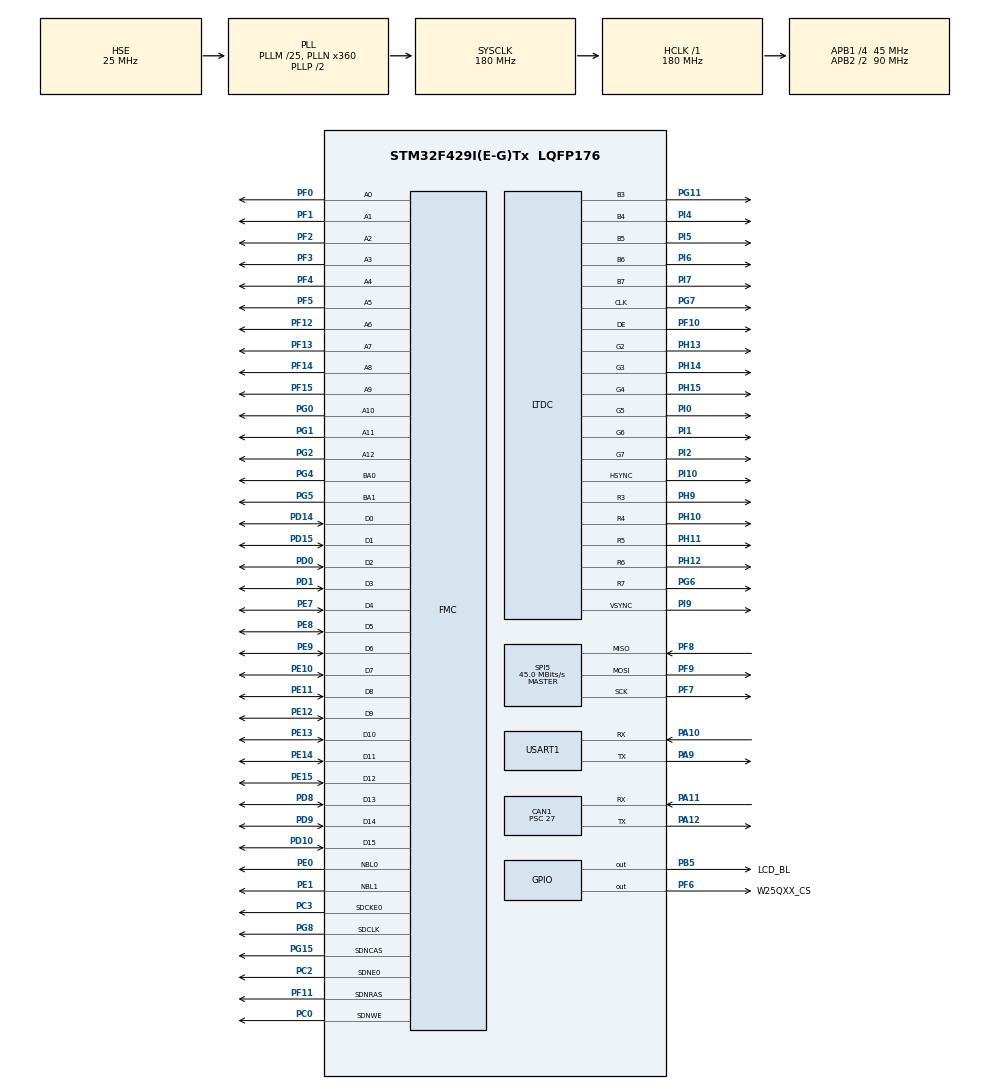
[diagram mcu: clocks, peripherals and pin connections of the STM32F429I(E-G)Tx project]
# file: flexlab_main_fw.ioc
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CAN1.ABOM=DISABLE
CAN1.AWUM=DISABLE
CAN1.BS1=CAN_BS1_5TQ
CAN1.BS2=CAN_BS2_5TQ
CAN1.CalculateBaudRate=151515
CAN1.CalculateTimeBit=6600
CAN1.CalculateTimeQuantum=600.0
CAN1.Mode=CAN_MODE_NORMAL
CAN1.NART=ENABLE
CAN1.Prescaler=27
DMA2D.ColorMode=DMA2D_OUTPUT_RGB565
FMC.CASLatency1=FMC_SDRAM_CAS_LATENCY_3
FMC.ColumnBitsNumber1=FMC_SDRAM_COLUMN_BITS_NUM_9
FMC.ExitSelfRefreshDelay1=8
FMC.LoadToActiveDelay1=2
FMC.RCDDelay1=2
FMC.RPDelay1=2
FMC.ReadBurst1=FMC_SDRAM_RBURST_ENABLE
FMC.ReadPipeDelay1=FMC_SDRAM_RPIPE_DELAY_1
FMC.RowCycleDelay1=6
FMC.SDClockPeriod1=FMC_SDRAM_CLOCK_PERIOD_2
FMC.SelfRefreshTime1=6
FMC.WriteRecoveryTime1=4
FREERTOS.Queues01=SettingTxQueue,3,Layer_SettingTypeDef,0,Dynamic,NULL,NULL;LayerNumQueue,3,uint8_t,0,Dynamic,NULL,NULL;LayerStatusQueue,3,q_Layer_StatusTypeDef,0,Dynamic,NULL,NULL;LayerBLRGBQueue,3,uint32_t,0,Dynamic,NULL,NULL;LayerCMDQueue,3,uint32_t,0,Dynamic,NULL,NULL;touch_posQueue,1,uint32_t,0,Dynamic,NULL,NULL;CarbinStatusQueue,3,q_Carbin_StatusTypeDef,0,Dynamic,NULL,NULL
FREERTOS.Tasks01=guiTask,24,4096,GUITask,Default,NULL,Dynamic,NULL,NULL;CANTransmitTask,8,128,CAN_TransmitTask,Default,NULL,Dynamic,NULL,NULL;getTouchTask,40,128,get_touchTask,Default,NULL,Dynamic,NULL,NULL
FREERTOS.configENABLE_FPU=1
FREERTOS.configTOTAL_HEAP_SIZE=32768
FREERTOS.configUSE_APPLICATION_TASK_TAG=1
FREERTOS.configUSE_COUNTING_SEMAPHORES=1
FREERTOS.configUSE_RECURSIVE_MUTEXES=1
LTDC.ActiveH=600
LTDC.ActiveW=1024
LTDC.Alpha_L0=255
LTDC.Alpha_L1=255
LTDC.BlendingFactor1_L0=LTDC_BLENDING_FACTOR1_CA
LTDC.BlendingFactor2_L0=LTDC_BLENDING_FACTOR2_CA
LTDC.FBStartAdress_L0=0xC0000000
LTDC.HBP=140
LTDC.HFP=160
LTDC.HSync=20
LTDC.ImageHeight_L0=600
LTDC.ImageWidth_L0=1024
LTDC.Layers=0
LTDC.PixelFormat_L0=LTDC_PIXEL_FORMAT_RGB565
LTDC.VBP=20
LTDC.VFP=12
LTDC.VSync=3
LTDC.WindowX1_L0=1024
LTDC.WindowY1_L0=600
Mcu.Family=STM32F4
Mcu.Name=STM32F429I(E-G)Tx
Mcu.Package=LQFP176
NVIC.CAN1_RX0_IRQn=true\:5\:0\:false\:false\:true\:true\:true\:true\:true
NVIC.DMA2D_IRQn=true\:5\:0\:false\:false\:true\:true\:true\:true\:true
NVIC.LTDC_IRQn=true\:5\:0\:true\:false\:true\:true\:true\:true\:true
NVIC.PriorityGroup=NVIC_PRIORITYGROUP_4
NVIC.TIM1_UP_TIM10_IRQn=true\:0\:0\:false\:false\:true\:false\:false\:true\:true
NVIC.TimeBase=TIM1_UP_TIM10_IRQn
NVIC.TimeBaseIP=TIM1
PA10.Mode=Asynchronous
PA10.Signal=USART1_RX
PA11.GPIO_PuPd=GPIO_PULLUP
PA11.Mode=CAN_Activate
PA11.Signal=CAN1_RX
PA12.GPIO_PuPd=GPIO_PULLUP
PA12.Mode=CAN_Activate
PA12.Signal=CAN1_TX
PA13.Mode=Serial_Wire
PA13.Signal=SYS_JTMS-SWDIO
PA14.Mode=Serial_Wire
PA14.Signal=SYS_JTCK-SWCLK
PA9.Mode=Asynchronous
PA9.Signal=USART1_TX
PB5.GPIO_Label=LCD_BL
PB5.GPIO_PuPd=GPIO_PULLUP
PB5.PinState=GPIO_PIN_SET
PB5.Signal=GPIO_Output
PC0.Signal=FMC_SDNWE
PC14/OSC32_IN.Mode=LSE-External-Oscillator
PC14/OSC32_IN.Signal=RCC_OSC32_IN
PC15/OSC32_OUT.Mode=LSE-External-Oscillator
PC15/OSC32_OUT.Signal=RCC_OSC32_OUT
PC2.Mode=SdramChipSelect1_1
PC2.Signal=FMC_SDNE0
PC3.Mode=SdramChipSelect1_1
PC3.Signal=FMC_SDCKE0
PD0.Signal=FMC_D2_DA2
PD1.Signal=FMC_D3_DA3
PD10.Signal=FMC_D15_DA15
PD14.Signal=FMC_D0_DA0
PD15.Signal=FMC_D1_DA1
PD8.Signal=FMC_D13_DA13
PD9.Signal=FMC_D14_DA14
PE0.Signal=FMC_NBL0
PE1.Signal=FMC_NBL1
PE10.Signal=FMC_D7_DA7
PE11.Signal=FMC_D8_DA8
PE12.Signal=FMC_D9_DA9
PE13.Signal=FMC_D10_DA10
PE14.Signal=FMC_D11_DA11
PE15.Signal=FMC_D12_DA12
PE7.Signal=FMC_D4_DA4
PE8.Signal=FMC_D5_DA5
PE9.Signal=FMC_D6_DA6
PF0.Signal=FMC_A0
PF1.Signal=FMC_A1
PF10.GPIO_Mode=GPIO_MODE_AF_PP
PF10.GPIO_PuPd=GPIO_NOPULL
PF10.GPIO_Speed=GPIO_SPEED_FREQ_VERY_HIGH
PF10.Mode=RGB565
PF10.Signal=LTDC_DE
PF11.Signal=FMC_SDNRAS
PF12.Signal=FMC_A6
PF13.Signal=FMC_A7
PF14.Signal=FMC_A8
PF15.Signal=FMC_A9
PF2.Signal=FMC_A2
PF3.Signal=FMC_A3
PF4.Signal=FMC_A4
PF5.Signal=FMC_A5
PF6.GPIO_Label=W25QXX_CS
PF6.GPIO_PuPd=GPIO_PULLUP
PF6.PinState=GPIO_PIN_SET
PF6.Signal=GPIO_Output
PF7.GPIO_PuPd=GPIO_PULLUP
PF7.Mode=Full_Duplex_Master
PF7.Signal=SPI5_SCK
PF8.GPIO_PuPd=GPIO_PULLUP
PF8.Mode=Full_Duplex_Master
PF8.Signal=SPI5_MISO
PF9.GPIO_PuPd=GPIO_PULLUP
PF9.Mode=Full_Duplex_Master
PF9.Signal=SPI5_MOSI
PG0.Signal=FMC_A10
PG1.Signal=FMC_A11
PG11.GPIO_Mode=GPIO_MODE_AF_PP
PG11.GPIO_PuPd=GPIO_NOPULL
PG11.GPIO_Speed=GPIO_SPEED_FREQ_VERY_HIGH
PG11.Mode=RGB565
PG11.Signal=LTDC_B3
PG15.Signal=FMC_SDNCAS
PG2.Signal=FMC_A12
PG4.Signal=FMC_A14_BA0
PG5.Signal=FMC_A15_BA1
PG6.GPIO_Mode=GPIO_MODE_AF_PP
PG6.GPIO_PuPd=GPIO_NOPULL
PG6.GPIO_Speed=GPIO_SPEED_FREQ_VERY_HIGH
PG6.Mode=RGB565
PG6.Signal=LTDC_R7
PG7.GPIO_Mode=GPIO_MODE_AF_PP
PG7.GPIO_PuPd=GPIO_NOPULL
PG7.GPIO_Speed=GPIO_SPEED_FREQ_VERY_HIGH
PG7.Mode=RGB565
PG7.Signal=LTDC_CLK
PG8.Signal=FMC_SDCLK
PH0/OSC_IN.Mode=HSE-External-Oscillator
PH0/OSC_IN.Signal=RCC_OSC_IN
PH1/OSC_OUT.Mode=HSE-External-Oscillator
PH1/OSC_OUT.Signal=RCC_OSC_OUT
PH10.GPIO_Mode=GPIO_MODE_AF_PP
PH10.GPIO_PuPd=GPIO_NOPULL
PH10.GPIO_Speed=GPIO_SPEED_FREQ_VERY_HIGH
PH10.Mode=RGB565
PH10.Signal=LTDC_R4
PH11.GPIO_Mode=GPIO_MODE_AF_PP
PH11.GPIO_PuPd=GPIO_NOPULL
PH11.GPIO_Speed=GPIO_SPEED_FREQ_VERY_HIGH
PH11.Mode=RGB565
PH11.Signal=LTDC_R5
PH12.GPIO_Mode=GPIO_MODE_AF_PP
PH12.GPIO_PuPd=GPIO_NOPULL
PH12.GPIO_Speed=GPIO_SPEED_FREQ_VERY_HIGH
PH12.Mode=RGB565
PH12.Signal=LTDC_R6
PH13.GPIO_Mode=GPIO_MODE_AF_PP
PH13.GPIO_PuPd=GPIO_NOPULL
PH13.GPIO_Speed=GPIO_SPEED_FREQ_VERY_HIGH
PH13.Mode=RGB565
PH13.Signal=LTDC_G2
PH14.GPIO_Mode=GPIO_MODE_AF_PP
PH14.GPIO_PuPd=GPIO_NOPULL
PH14.GPIO_Speed=GPIO_SPEED_FREQ_VERY_HIGH
PH14.Mode=RGB565
PH14.Signal=LTDC_G3
PH15.GPIO_Mode=GPIO_MODE_AF_PP
PH15.GPIO_PuPd=GPIO_NOPULL
PH15.GPIO_Speed=GPIO_SPEED_FREQ_VERY_HIGH
PH15.Mode=RGB565
PH15.Signal=LTDC_G4
PH9.GPIO_Mode=GPIO_MODE_AF_PP
PH9.GPIO_PuPd=GPIO_NOPULL
PH9.GPIO_Speed=GPIO_SPEED_FREQ_VERY_HIGH
PH9.Mode=RGB565
PH9.Signal=LTDC_R3
PI0.GPIO_Mode=GPIO_MODE_AF_PP
PI0.GPIO_PuPd=GPIO_NOPULL
PI0.GPIO_Speed=GPIO_SPEED_FREQ_VERY_HIGH
PI0.Mode=RGB565
PI0.Signal=LTDC_G5
PI1.GPIO_Mode=GPIO_MODE_AF_PP
PI1.GPIO_PuPd=GPIO_NOPULL
PI1.GPIO_Speed=GPIO_SPEED_FREQ_VERY_HIGH
PI1.Mode=RGB565
PI1.Signal=LTDC_G6
PI10.GPIO_Mode=GPIO_MODE_AF_PP
PI10.GPIO_PuPd=GPIO_NOPULL
PI10.GPIO_Speed=GPIO_SPEED_FREQ_VERY_HIGH
PI10.Mode=RGB565
PI10.Signal=LTDC_HSYNC
PI2.GPIO_Mode=GPIO_MODE_AF_PP
PI2.GPIO_PuPd=GPIO_NOPULL
PI2.GPIO_Speed=GPIO_SPEED_FREQ_VERY_HIGH
PI2.Mode=RGB565
PI2.Signal=LTDC_G7
PI4.GPIO_Mode=GPIO_MODE_AF_PP
PI4.GPIO_PuPd=GPIO_NOPULL
PI4.GPIO_Speed=GPIO_SPEED_FREQ_VERY_HIGH
PI4.Mode=RGB565
PI4.Signal=LTDC_B4
PI5.GPIO_Mode=GPIO_MODE_AF_PP
PI5.GPIO_PuPd=GPIO_NOPULL
PI5.GPIO_Speed=GPIO_SPEED_FREQ_VERY_HIGH
PI5.Mode=RGB565
PI5.Signal=LTDC_B5
PI6.GPIO_Mode=GPIO_MODE_AF_PP
PI6.GPIO_PuPd=GPIO_NOPULL
PI6.GPIO_Speed=GPIO_SPEED_FREQ_VERY_HIGH
PI6.Mode=RGB565
PI6.Signal=LTDC_B6
PI7.GPIO_Mode=GPIO_MODE_AF_PP
PI7.GPIO_PuPd=GPIO_NOPULL
PI7.GPIO_Speed=GPIO_SPEED_FREQ_VERY_HIGH
PI7.Mode=RGB565
PI7.Signal=LTDC_B7
PI9.GPIO_Mode=GPIO_MODE_AF_PP
PI9.GPIO_PuPd=GPIO_NOPULL
PI9.GPIO_Speed=GPIO_SPEED_FREQ_VERY_HIGH
PI9.Mode=RGB565
PI9.Signal=LTDC_VSYNC
ProjectManager.HeapSize=0x200
ProjectManager.StackSize=0x400
ProjectManager.TargetToolchain=MDK-ARM V5.27
RCC.48MHZClocksFreq_Value=45000000
RCC.AHBFreq_Value=180000000
RCC.APB1CLKDivider=RCC_HCLK_DIV4
RCC.APB1Freq_Value=45000000
RCC.APB1TimFreq_Value=90000000
RCC.APB2CLKDivider=RCC_HCLK_DIV2
RCC.APB2Freq_Value=90000000
RCC.APB2TimFreq_Value=180000000
RCC.CortexFreq_Value=180000000
RCC.EnbaleCSS=true
RCC.HCLKFreq_Value=180000000
RCC.HSE_VALUE=25000000
RCC.HSI_VALUE=16000000
RCC.PLLM=25
RCC.PLLN=360
RCC.PLLQ=8
RCC.PLLSAIDivR=RCC_PLLSAIDIVR_4
RCC.PLLSAIN=340
RCC.PLLSourceVirtual=RCC_PLLSOURCE_HSE
RCC.RCC_RTC_Clock_Source=RCC_RTCCLKSOURCE_LSE
RCC.RCC_RTC_Clock_SourceVirtual=RCC_RTCCLKSOURCE_LSE
RCC.SYSCLKFreq_VALUE=180000000
RCC.SYSCLKSource=RCC_SYSCLKSOURCE_PLLCLK
RCC.VCOOutputFreq_Value=360000000
SH.FMC_A0.0=FMC_A0,13b-sda1
SH.FMC_A1.0=FMC_A1,13b-sda1
SH.FMC_A10.0=FMC_A10,13b-sda1
SH.FMC_A11.0=FMC_A11,13b-sda1
SH.FMC_A12.0=FMC_A12,13b-sda1
SH.FMC_A14_BA0.0=FMC_BA0,FourSdramBanks1
SH.FMC_A15_BA1.0=FMC_BA1,FourSdramBanks1
SH.FMC_A2.0=FMC_A2,13b-sda1
SH.FMC_A3.0=FMC_A3,13b-sda1
SH.FMC_A4.0=FMC_A4,13b-sda1
SH.FMC_A5.0=FMC_A5,13b-sda1
SH.FMC_A6.0=FMC_A6,13b-sda1
SH.FMC_A7.0=FMC_A7,13b-sda1
SH.FMC_A8.0=FMC_A8,13b-sda1
SH.FMC_A9.0=FMC_A9,13b-sda1
SH.FMC_D0_DA0.0=FMC_D0,sd-16b-d1
SH.FMC_D10_DA10.0=FMC_D10,sd-16b-d1
SH.FMC_D11_DA11.0=FMC_D11,sd-16b-d1
SH.FMC_D12_DA12.0=FMC_D12,sd-16b-d1
SH.FMC_D13_DA13.0=FMC_D13,sd-16b-d1
SH.FMC_D14_DA14.0=FMC_D14,sd-16b-d1
SH.FMC_D15_DA15.0=FMC_D15,sd-16b-d1
SH.FMC_D1_DA1.0=FMC_D1,sd-16b-d1
SH.FMC_D2_DA2.0=FMC_D2,sd-16b-d1
SH.FMC_D3_DA3.0=FMC_D3,sd-16b-d1
SH.FMC_D4_DA4.0=FMC_D4,sd-16b-d1
SH.FMC_D5_DA5.0=FMC_D5,sd-16b-d1
SH.FMC_D6_DA6.0=FMC_D6,sd-16b-d1
SH.FMC_D7_DA7.0=FMC_D7,sd-16b-d1
SH.FMC_D8_DA8.0=FMC_D8,sd-16b-d1
SH.FMC_D9_DA9.0=FMC_D9,sd-16b-d1
SH.FMC_NBL0.0=FMC_NBL0,Sd2ByteEnable1
SH.FMC_NBL1.0=FMC_NBL1,Sd2ByteEnable1
SH.FMC_SDCLK.0=FMC_SDCLK,13b-sda1
SH.FMC_SDNCAS.0=FMC_SDNCAS,13b-sda1
SH.FMC_SDNRAS.0=FMC_SDNRAS,13b-sda1
SH.FMC_SDNWE.0=FMC_SDNWE,13b-sda1
SPI5.BaudRatePrescaler=SPI_BAUDRATEPRESCALER_2
SPI5.CLKPhase=SPI_PHASE_2EDGE
SPI5.CLKPolarity=SPI_POLARITY_HIGH
SPI5.CalculateBaudRate=45.0 MBits/s
SPI5.Direction=SPI_DIRECTION_2LINES
SPI5.Mode=SPI_MODE_MASTER
SPI5.VirtualType=VM_MASTER
STMicroelectronics.X-CUBE-TOUCHGFX.4.20.0.ApplicationCcGraphicsJjApplication=TouchGFXOoGenerator
STMicroelectronics.X-CUBE-TOUCHGFX.4.20.0.tgfx_address1=0xC0200000
STMicroelectronics.X-CUBE-TOUCHGFX.4.20.0.tgfx_address2=0xC0400000
STMicroelectronics.X-CUBE-TOUCHGFX.4.20.0.tgfx_buffering_strategy=Double
STMicroelectronics.X-CUBE-TOUCHGFX.4.20.0.tgfx_display_interface=disp_ltdc
STMicroelectronics.X-CUBE-TOUCHGFX.4.20.0.tgfx_hardware_accelerator=dma_2d
STMicroelectronics.X-CUBE-TOUCHGFX.4.20.0.tgfx_location=By Address
STMicroelectronics.X-CUBE-TOUCHGFX.4.20.0.tgfx_vsync=vsync_ltdc
USART1.VirtualMode=VM_ASYNC
VP_CRC_VS_CRC.Mode=CRC_Activate
VP_DMA2D_VS_DMA2D.Mode=DMA2D_Activate
VP_FREERTOS_VS_CMSIS_V2.Mode=CMSIS_V2
VP_RTC_VS_RTC_Activate.Mode=RTC_Enabled
VP_STMicroelectronics.X-CUBE-TOUCHGFX_VS_GraphicsJjApplication_4.20.0.Mode=GraphicsJjApplication
VP_SYS_VS_tim1.Mode=TIM1
board=custom

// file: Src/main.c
/* USER CODE BEGIN Header */
/**
  ******************************************************************************
  * @file           : main.c
  * @brief          : Main program body
  ******************************************************************************
  * @attention
  *
  * <h2><center>&copy; Copyright (c) 2021 STMicroelectronics.
  * All rights reserved.</center></h2>
  *
  * This software component is licensed by ST under Ultimate Liberty license
  * SLA0044, the "License"; You may not use this file except in compliance with
  * the License. You may obtain a copy of the License at:
  *                             www.st.com/SLA0044
  *
  ******************************************************************************
  */
/* USER CODE END Header */
#include "main.h"
#include "cmsis_os.h"
#include "can.h"
#include "crc.h"
#include "dma2d.h"
#include "ltdc.h"
#include "rtc.h"
#include "spi.h"
#include "usart.h"
#include "gpio.h"
#include "fmc.h"
#include "app_touchgfx.h"

/* USER CODE BEGIN Includes */
#include "w25qxx.h"
/* USER CODE END Includes */

void SystemClock_Config(void);
void MX_FREERTOS_Init(void);

/* USER CODE BEGIN 0 */
#define REFRESH_COUNT                            683
#define SDRAM_MODEREG_BURST_LENGTH_1             ((uint16_t)0x0000)
#define SDRAM_MODEREG_BURST_LENGTH_2             ((uint16_t)0x0001)
#define SDRAM_MODEREG_BURST_LENGTH_4             ((uint16_t)0x0002)
#define SDRAM_MODEREG_BURST_LENGTH_8             ((uint16_t)0x0004)
#define SDRAM_MODEREG_BURST_TYPE_SEQUENTIAL      ((uint16_t)0x0000)
#define SDRAM_MODEREG_BURST_TYPE_INTERLEAVED     ((uint16_t)0x0008)
#define SDRAM_MODEREG_CAS_LATENCY_2              ((uint16_t)0x0020)
#define SDRAM_MODEREG_CAS_LATENCY_3              ((uint16_t)0x0030)
#define SDRAM_MODEREG_OPERATING_MODE_STANDARD    ((uint16_t)0x0000)
#define SDRAM_MODEREG_WRITEBURST_MODE_PROGRAMMED ((uint16_t)0x0000)
#define SDRAM_MODEREG_WRITEBURST_MODE_SINGLE     ((uint16_t)0x0200)
#define SDRAM_TIMEOUT      								       ((uint16_t)0xFFFF)

uint8_t SDRAM_Send_Cmd(uint32_t bankx,uint8_t cmd,uint8_t refresh,uint16_t regval)
{
    FMC_SDRAM_CommandTypeDef Command;

    Command.CommandMode=cmd;                //命令
    Command.CommandTarget=bankx;      //目标SDRAM存储区域
    Command.AutoRefreshNumber=refresh;      //自刷新次数
    Command.ModeRegisterDefinition=regval;  //要写入模式寄存器的值
    if(HAL_SDRAM_SendCommand(&hsdram1,&Command,0X1000)==HAL_OK) //向SDRAM发送命令
    {
        return 0;
    }
    else return 1;
}

void MX_SDRAM_InitEx(void)
{
	uint32_t temp=0;
	//SDRAM控制器初始化完成以后还需要按照如下顺序初始化SDRAM
	SDRAM_Send_Cmd(FMC_SDRAM_CMD_TARGET_BANK1,FMC_SDRAM_CMD_CLK_ENABLE,1,0); //时钟配置使能
	HAL_Delay(1);                                  //至少延时200us
	SDRAM_Send_Cmd(FMC_SDRAM_CMD_TARGET_BANK1,FMC_SDRAM_CMD_PALL,1,0);       //对所有存储区预充电
	SDRAM_Send_Cmd(FMC_SDRAM_CMD_TARGET_BANK1,FMC_SDRAM_CMD_AUTOREFRESH_MODE,8,0);//设置自刷新次数
	//配置模式寄存器,SDRAM的bit0~bit2为指定突发访问的长度，
	//bit3为指定突发访问的类型，bit4~bit6为CAS值，bit7和bit8为运行模式
	//bit9为指定的写突发模式，bit10和bit11位保留位
	temp=(uint32_t)SDRAM_MODEREG_BURST_LENGTH_8     |	//设置突发长度:1(可以是1/2/4/8)
						SDRAM_MODEREG_BURST_TYPE_SEQUENTIAL   |	//设置突发类型:连续(可以是连续/交错)
						SDRAM_MODEREG_CAS_LATENCY_3           |	//设置CAS值:3(可以是2/3)
						SDRAM_MODEREG_OPERATING_MODE_STANDARD |   //设置操作模式:0,标准模式
						SDRAM_MODEREG_WRITEBURST_MODE_SINGLE;     //设置突发写模式:1,单点访问
	SDRAM_Send_Cmd(FMC_SDRAM_CMD_TARGET_BANK1,FMC_SDRAM_CMD_LOAD_MODE,1,temp);   //设置SDRAM的模式寄存器

	//刷新频率计数器(以SDCLK频率计数),计算方法:
	//COUNT=SDRAM刷新周期/行数-20=SDRAM刷新周期(us)*SDCLK频率(Mhz)/行数
	//我们使用的SDRAM刷新周期为64ms,SDCLK=180/2=90Mhz,行数为8192(2^13).
	//所以,COUNT=64*1000*90/8192-20=683
	HAL_SDRAM_ProgramRefreshRate(&hsdram1,683);

}
/* USER CODE END 0 */

int main(void)
{

  /* MCU Configuration--------------------------------------------------------*/

  /* Reset of all peripherals, Initializes the Flash interface and the Systick. */
  HAL_Init();

  /* Configure the system clock */
  SystemClock_Config();

  /* Initialize all configured peripherals */
  MX_GPIO_Init();
  MX_CRC_Init();
  MX_DMA2D_Init();
  MX_FMC_Init();
  MX_LTDC_Init();
  MX_USART1_UART_Init();
  MX_RTC_Init();
  MX_SPI5_Init();
  MX_CAN1_Init();
  MX_TouchGFX_Init();
  /* USER CODE BEGIN 2 */
	MX_SDRAM_InitEx();
	W25QXX_Init();

  /* USER CODE END 2 */

  /* Init scheduler */
  osKernelInitialize();  /* Call init function for freertos objects (in freertos.c) */
  MX_FREERTOS_Init();
  /* Start scheduler */
  osKernelStart();

  /* We should never get here as control is now taken by the scheduler */
  /* Infinite loop */
  while (1)
  {

  }
}

void SystemClock_Config(void)
{
  RCC_OscInitTypeDef RCC_OscInitStruct = {0};
  RCC_ClkInitTypeDef RCC_ClkInitStruct = {0};

  /** Configure the main internal regulator output voltage
  */
  __HAL_RCC_PWR_CLK_ENABLE();
  __HAL_PWR_VOLTAGESCALING_CONFIG(PWR_REGULATOR_VOLTAGE_SCALE1);
  /** Initializes the RCC Oscillators according to the specified parameters
  * in the RCC_OscInitTypeDef structure.
  */
  RCC_OscInitStruct.OscillatorType = RCC_OSCILLATORTYPE_HSE|RCC_OSCILLATORTYPE_LSE;
  RCC_OscInitStruct.HSEState = RCC_HSE_ON;
  RCC_OscInitStruct.LSEState = RCC_LSE_ON;
  RCC_OscInitStruct.PLL.PLLState = RCC_PLL_ON;
  RCC_OscInitStruct.PLL.PLLSource = RCC_PLLSOURCE_HSE;
  RCC_OscInitStruct.PLL.PLLM = 25;
  RCC_OscInitStruct.PLL.PLLN = 360;
  RCC_OscInitStruct.PLL.PLLP = RCC_PLLP_DIV2;
  RCC_OscInitStruct.PLL.PLLQ = 8;
  if (HAL_RCC_OscConfig(&RCC_OscInitStruct) != HAL_OK)
  {
    Error_Handler();
  }
  /** Activate the Over-Drive mode
  */
  if (HAL_PWREx_EnableOverDrive() != HAL_OK)
  {
    Error_Handler();
  }
  /** Initializes the CPU, AHB and APB buses clocks
  */
  RCC_ClkInitStruct.ClockType = RCC_CLOCKTYPE_HCLK|RCC_CLOCKTYPE_SYSCLK
                              |RCC_CLOCKTYPE_PCLK1|RCC_CLOCKTYPE_PCLK2;
  RCC_ClkInitStruct.SYSCLKSource = RCC_SYSCLKSOURCE_PLLCLK;
  RCC_ClkInitStruct.AHBCLKDivider = RCC_SYSCLK_DIV1;
  RCC_ClkInitStruct.APB1CLKDivider = RCC_HCLK_DIV4;
  RCC_ClkInitStruct.APB2CLKDivider = RCC_HCLK_DIV2;

  if (HAL_RCC_ClockConfig(&RCC_ClkInitStruct, FLASH_LATENCY_5) != HAL_OK)
  {
    Error_Handler();
  }
  /** Enables the Clock Security System
  */
  HAL_RCC_EnableCSS();
}

void HAL_TIM_PeriodElapsedCallback(TIM_HandleTypeDef *htim)
{
  if (htim->Instance == TIM1) {
    HAL_IncTick();
  }
}

void Error_Handler(void)
{
  __disable_irq();
  while (1)
  {
  }
}

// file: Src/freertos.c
/* USER CODE BEGIN Header */
/**
  ******************************************************************************
  * File Name          : freertos.c
  * Description        : Code for freertos applications
  ******************************************************************************
  * @attention
  *
  * <h2><center>&copy; Copyright (c) 2021 STMicroelectronics.
  * All rights reserved.</center></h2>
  *
  * This software component is licensed by ST under Ultimate Liberty license
  * SLA0044, the "License"; You may not use this file except in compliance with
  * the License. You may obtain a copy of the License at:
  *                             www.st.com/SLA0044
  *
  ******************************************************************************
  */
/* USER CODE END Header */

#include "FreeRTOS.h"
#include "task.h"
#include "main.h"
#include "cmsis_os.h"

/* USER CODE BEGIN Includes */
#include "stdio.h"
#include "app_touchgfx.h"
#include "can.h"
#include "layer_define.h"
#include "rtc.h"

#ifdef FT5206_TOUCH_DRIVER
#include "ft5206.h"
#else
#include "gt9147.h"
#endif
/* USER CODE END Includes */

/* USER CODE BEGIN PD */
#define the_x 0
#define the_y 1
/* USER CODE END PD */

/* USER CODE BEGIN Variables */
extern uint8_t Rx_Data[8];
extern uint32_t ID;
extern uint8_t CAN_RX_Flag;
/* USER CODE END Variables */
/* Definitions for guiTask */
osThreadId_t guiTaskHandle;
const osThreadAttr_t guiTask_attributes = {
  .name = "guiTask",
  .stack_size = 4096 * 4,
  .priority = (osPriority_t) osPriorityNormal,
};
/* Definitions for CANTransmitTask */
osThreadId_t CANTransmitTaskHandle;
const osThreadAttr_t CANTransmitTask_attributes = {
  .name = "CANTransmitTask",
  .stack_size = 128 * 4,
  .priority = (osPriority_t) osPriorityLow,
};
/* Definitions for getTouchTask */
osThreadId_t getTouchTaskHandle;
const osThreadAttr_t getTouchTask_attributes = {
  .name = "getTouchTask",
  .stack_size = 128 * 4,
  .priority = (osPriority_t) osPriorityHigh,
};
/* Definitions for SettingTxQueue */
osMessageQueueId_t SettingTxQueueHandle;
const osMessageQueueAttr_t SettingTxQueue_attributes = {
  .name = "SettingTxQueue"
};
/* Definitions for LayerNumQueue */
osMessageQueueId_t LayerNumQueueHandle;
const osMessageQueueAttr_t LayerNumQueue_attributes = {
  .name = "LayerNumQueue"
};
/* Definitions for LayerStatusQueue */
osMessageQueueId_t LayerStatusQueueHandle;
const osMessageQueueAttr_t LayerStatusQueue_attributes = {
  .name = "LayerStatusQueue"
};
/* Definitions for LayerBLRGBQueue */
osMessageQueueId_t LayerBLRGBQueueHandle;
const osMessageQueueAttr_t LayerBLRGBQueue_attributes = {
  .name = "LayerBLRGBQueue"
};
/* Definitions for LayerCMDQueue */
osMessageQueueId_t LayerCMDQueueHandle;
const osMessageQueueAttr_t LayerCMDQueue_attributes = {
  .name = "LayerCMDQueue"
};
/* Definitions for touch_posQueue */
osMessageQueueId_t touch_posQueueHandle;
const osMessageQueueAttr_t touch_posQueue_attributes = {
  .name = "touch_posQueue"
};
/* Definitions for CarbinStatusQueue */
osMessageQueueId_t CarbinStatusQueueHandle;
const osMessageQueueAttr_t CarbinStatusQueue_attributes = {
  .name = "CarbinStatusQueue"
};

void GUITask(void *argument);
void CAN_TransmitTask(void *argument);
void get_touchTask(void *argument);

void MX_FREERTOS_Init(void); /* (MISRA C 2004 rule 8.1) */

void MX_FREERTOS_Init(void) {

  /* Create the queue(s) */
  /* creation of SettingTxQueue */
  SettingTxQueueHandle = osMessageQueueNew (3, sizeof(Layer_SettingTypeDef), &SettingTxQueue_attributes);

  /* creation of LayerNumQueue */
  LayerNumQueueHandle = osMessageQueueNew (3, sizeof(uint8_t), &LayerNumQueue_attributes);

  /* creation of LayerStatusQueue */
  LayerStatusQueueHandle = osMessageQueueNew (3, sizeof(q_Layer_StatusTypeDef), &LayerStatusQueue_attributes);

  /* creation of LayerBLRGBQueue */
  LayerBLRGBQueueHandle = osMessageQueueNew (3, sizeof(uint32_t), &LayerBLRGBQueue_attributes);

  /* creation of LayerCMDQueue */
  LayerCMDQueueHandle = osMessageQueueNew (3, sizeof(uint32_t), &LayerCMDQueue_attributes);

  /* creation of touch_posQueue */
  touch_posQueueHandle = osMessageQueueNew (1, sizeof(uint32_t), &touch_posQueue_attributes);

  /* creation of CarbinStatusQueue */
  CarbinStatusQueueHandle = osMessageQueueNew (3, sizeof(q_Carbin_StatusTypeDef), &CarbinStatusQueue_attributes);

  /* Create the thread(s) */
  /* creation of guiTask */
  guiTaskHandle = osThreadNew(GUITask, NULL, &guiTask_attributes);

  /* creation of CANTransmitTask */
  CANTransmitTaskHandle = osThreadNew(CAN_TransmitTask, NULL, &CANTransmitTask_attributes);

  /* creation of getTouchTask */
  getTouchTaskHandle = osThreadNew(get_touchTask, NULL, &getTouchTask_attributes);

}

void GUITask(void *argument)
{
  /* USER CODE BEGIN GUITask */
  /* Infinite loop */
  for(;;)
  {
    MX_TouchGFX_Process();
    osDelay(5);
  }
  /* USER CODE END GUITask */
}

void CAN_TransmitTask(void *argument)
{
  /* USER CODE BEGIN CAN_TransmitTask */
	RTC_TimeTypeDef sTime;
	RTC_DateTypeDef sDate;
	uint8_t layer_num;

	union	layer_settings
	{
		Layer_SettingTypeDef menber;
		uint8_t buf[27];
	}layer_settings;

	union	layer_status
	{
		q_Layer_StatusTypeDef menber;
		uint8_t buf[5];
	}layer_status;

	union	carbin_status
	{
		q_Carbin_StatusTypeDef menber;
		uint8_t buf[2];
	}carbin_status;

	union RGB
	{
		uint32_t data;
		uint8_t buf[4];
	}RGB;

	union CMD
	{
		uint32_t data;
		uint8_t buf[4];
	}CMD;

	uint8_t buf[7][8];
  /* Infinite loop */
  for(;;)
  {
		if(CAN_RX_Flag)
		{
			if(Rx_Data[0]==0x07)
			{
				for(uint8_t i=0;i<4;i++)
					layer_status.buf[i]=Rx_Data[1+i];

				layer_status.buf[4]=ID;
				const q_Layer_StatusTypeDef q_Layer_Status=layer_status.menber;
				osMessageQueuePut(LayerStatusQueueHandle, &q_Layer_Status, 1, 0);
			}
			else if(Rx_Data[0]==0x82)
			{
				for(uint8_t i=0;i<2;i++)
					carbin_status.buf[i]=Rx_Data[1+i];

				const q_Carbin_StatusTypeDef q_Carbin_Status=carbin_status.menber;
				osMessageQueuePut(CarbinStatusQueueHandle, &q_Carbin_Status, 1, 0);
			}

			CAN_RX_Flag=0;
		}
		else if(osMessageQueueGetSpace(SettingTxQueueHandle)!=3&&
						osMessageQueueGetSpace(LayerNumQueueHandle)!=3
					 )
		{
			osMessageQueueGet(SettingTxQueueHandle, &layer_settings.menber, (uint8_t *)1, 50);
			osMessageQueueGet(LayerNumQueueHandle, &layer_num, (uint8_t *)1, 50);

			for(uint8_t i=0;i<7;i++)
			{
				buf[i][0]=i;
				switch(i)
				{
					case 0:
						buf[i][1]=layer_settings.buf[0];
						buf[i][2]=sTime.Hours;
						buf[i][3]=sTime.Minutes;
						buf[i][4]=layer_settings.buf[1];
						buf[i][5]=layer_settings.buf[2];
						buf[i][6]=layer_settings.buf[3];
					break;

					case 1:
						buf[i][1]=layer_settings.buf[4];
						buf[i][2]=layer_settings.buf[5];
						buf[i][3]=layer_settings.buf[6];
					break;

					case 2:
						buf[i][1]=layer_settings.buf[7];
						buf[i][2]=layer_settings.buf[8];
						buf[i][3]=layer_settings.buf[9];
						buf[i][4]=layer_settings.buf[10];
					break;

					case 3:
						buf[i][1]=layer_settings.buf[11];
						buf[i][2]=layer_settings.buf[12];
						buf[i][3]=layer_settings.buf[13];
						buf[i][4]=layer_settings.buf[14];
					break;

					case 4:
						buf[i][1]=layer_settings.buf[15];
						buf[i][2]=layer_settings.buf[16];
						buf[i][3]=layer_settings.buf[17];
						buf[i][4]=layer_settings.buf[18];
					break;

					case 5:
						buf[i][1]=layer_settings.buf[19];
						buf[i][2]=layer_settings.buf[20];
						buf[i][3]=layer_settings.buf[21];
						buf[i][4]=layer_settings.buf[22];
					break;

					case 6:
						buf[i][1]=layer_settings.buf[23];
						buf[i][2]=layer_settings.buf[24];
						buf[i][3]=layer_settings.buf[25];
						buf[i][4]=layer_settings.buf[26];
					break;

					default:break;
				}
				Can_TxMessage(0,0x100+layer_num,8,buf[i]);
			}
		}
		else if(osMessageQueueGetSpace(LayerBLRGBQueueHandle)!=3&&
						osMessageQueueGetSpace(LayerNumQueueHandle)!=3
					 )
		{
			osMessageQueueGet(LayerBLRGBQueueHandle, &RGB.data, (uint8_t *)1, 50);
			osMessageQueueGet(LayerNumQueueHandle, &layer_num, (uint8_t *)1, 50);

			buf[0][0]=0x08;
			buf[0][1]=RGB.buf[0];
			buf[0][2]=RGB.buf[1];
			buf[0][3]=RGB.buf[2];
			buf[0][4]=RGB.buf[3];

			Can_TxMessage(0,0x100+layer_num,8,buf[0]);
		}
		else if(osMessageQueueGetSpace(LayerCMDQueueHandle)!=3&&
						osMessageQueueGetSpace(LayerNumQueueHandle)!=3
					 )
		{
			osMessageQueueGet(LayerCMDQueueHandle, &CMD.data, (uint8_t *)1, 50);
			osMessageQueueGet(LayerNumQueueHandle, &layer_num, (uint8_t *)1, 50);

			buf[0][0]=0x09;
			buf[0][1]=CMD.buf[0];
			buf[0][2]=CMD.buf[1];
			buf[0][3]=CMD.buf[2];
			buf[0][4]=CMD.buf[3];

			Can_TxMessage(0,0x100+layer_num,8,buf[0]);
		}
		else
		{
			if(osMessageQueueGetSpace(LayerStatusQueueHandle)==3)
			{
				static uint8_t i=1;
				HAL_RTC_GetTime(&hrtc, &sTime, RTC_FORMAT_BIN);
				HAL_RTC_GetDate(&hrtc, &sDate, RTC_FORMAT_BIN);
				buf[0][0]=0x07;
				buf[0][1]=sTime.Hours;
				buf[0][2]=sTime.Minutes;
				buf[0][3]=sDate.Year;
				buf[0][4]=sDate.Month;
				buf[0][5]=sDate.Date;
//				for(uint8_t i=1;i<=3;i++)   //layer state report cmd
				Can_TxMessage(0,0x100+i,8,buf[0]);
				i++;
				if(i>3)
				{
					i=1;
					buf[0][0]=0x02;
					Can_TxMessage(0,0x200,8,buf[0]);
				}
			}
		}

    osDelay(5);
  }
  /* USER CODE END CAN_TransmitTask */
}

void get_touchTask(void *argument)
{
  /* USER CODE BEGIN get_touchTask */
  /* Infinite loop */
	union t_pos
	{
		uint32_t data;
		uint16_t buf[2];
	}t_pos;
  for(;;)
  {
#ifdef FT5206_TOUCH_DRIVER
		if(get_touch(&t_pos.buf[the_x],&t_pos.buf[the_y])==1)
		{
#else
		if(gt_get_touch(&t_pos.buf[the_x],&t_pos.buf[the_y])==1)
		{
#endif
			osMessageQueuePut(touch_posQueueHandle, &t_pos.data, 1, 1);
		}
			osDelay(5);
  }
  /* USER CODE END get_touchTask */
}
